# I2C0_CFG register map
Vendor: Texas Instruments
Peripheral module from a debugger description file (folder am65x).
Registers are 32-bit, access per field, reset 0x0 unless marked. A register's access mark holds for its fields unless they carry their own. Offsets are as the file gives them; lines under a group give offsets from that group; [hi:lo] are bit positions; {n}, {i} and the like mark numbered series; 'fields as' and 'values as' point back to an identical list; <NAME> marks a mode.

## I2C0_CFG
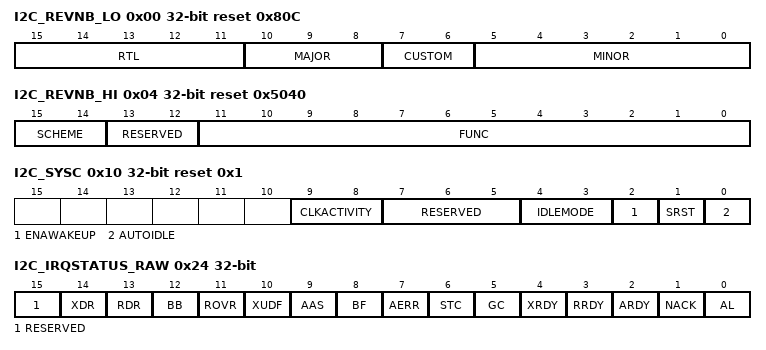
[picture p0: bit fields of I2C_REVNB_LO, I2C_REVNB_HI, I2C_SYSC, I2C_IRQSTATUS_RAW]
0x00 I2C_REVNB_LO ro reset 0x80C — Module Revision Identifier Used by software to track features, bugs, and compatibility
  [15:11] RTL — RTL version This field changes on bug fix, and resets to
  [10:8] MAJOR — Major Revision This field changes when there is a major feature change This field does not change due to bug fix, or minor feature change
  [7:6] CUSTOM — Indicates a special version for a particular device Consequence of use may avoid use of standard Chip Support Library [CSL] / Drivers 0 if non-custom
  [5:0] MINOR — Minor Revision This field changes when features are scaled up or down This field does not change due to bug fix, or major feature change
0x04 I2C_REVNB_HI ro reset 0x5040 — Module Revision Identifeir Used by software to track features, bugs, and compatibility
  [15:14] SCHEME — Used to distinguish between old Scheme and current Spare bit to encode future schemes
  [13:12] RESERVED — Reads return 0x1
  [11:0] FUNC — Function: Indicates a software compatible module family
0x10 I2C_SYSC reset 0x1 — System Configuration register
  [9:8] CLKACTIVITY rw — Clock Activity selection bits
  [7:5] RESERVED ro — Reads return 0
  [4:3] IDLEMODE rw — Idle Mode selection bits
  [2] ENAWAKEUP rw — Enable Wakeup control bit
  [1] SRST rw — SoftReset bit
  [0] AUTOIDLE rw — Autoidle bit
0x20 I2C_EOI — End Of Interrupt number specification Added Information About I2C_EOI Register The EOI register is used to re-trigger the pulse interrupt signal to ensure that any nested interrupt events are serviced. The software interrupt handler must write to the EOI register at the end of the current interrupt processing routine, so that new events can re-trigger the pulse interrupt signal again. For level interrupt signals the EOI register is not functional and must not be used.
  [0] LINE_NUMBER wo — Software End Of Interrupt (EOI) control. Write number of interrupt output.
0x24 I2C_IRQSTATUS_RAW — Per-event raw interrupt status vector. The raw status is set even if event is not enabled. Write 1 to set the (raw) status. Used mostly for debug
  [15] RESERVED rw — Write 0s for future compatibility Read returns 0
  [14] XDR rw — Transmit draining IRQ status.
  [13] RDR rw — Receive draining IRQ status.
  [12] BB ro — Bus busy status. Writing into this bit has no effect.
  [11] ROVR rw — Receive overrun status. Writing into this bit has no effect.
  [10] XUDF rw — Transmit underflow status. Writing into this bit has no effect.
  [9] AAS rw — Address recognized as slave IRQ status.
  [8] BF rw — Bus Free IRQ status.
  [7] AERR rw — Access Error IRQ status.
  [6] STC rw — Start Condition IRQ status.
  [5] GC rw — General call IRQ status. Set to 1 by core when General call address detected and interrupt signaled to IRQ_Crossbar.
  [4] XRDY rw — Transmit data ready IRQ status. Set to 1 by core when transmitter and when new data is requested. When set to 1 by core, an interrupt is signaled to IRQ_Crossbar.
  [3] RRDY rw — Receive data ready IRQ status. Set to 1 by core when receiver mode, a new data is able to be read. When set to 1 by core, an interrupt is signaled to IRQ_Crossbar.
  [2] ARDY rw — Register access ready IRQ status. When set to 1 it indicates that previous access has been performed and registers are ready to be accessed again. An interrupt is signaled to IRQ_Crossbar.
  [1] NACK rw — No acknowledgement IRQ status. Bit is set when No Acknowledge has been received, an interrupt is signaled to IRQ_Crossbar.
  [0] AL rw — Arbitration lost IRQ status. This bit is automatically set by the hardware when it loses the Arbitration in master transmit mode, an interrupt is signaled to IRQ_Crossbar. During reads, it always returns 0.
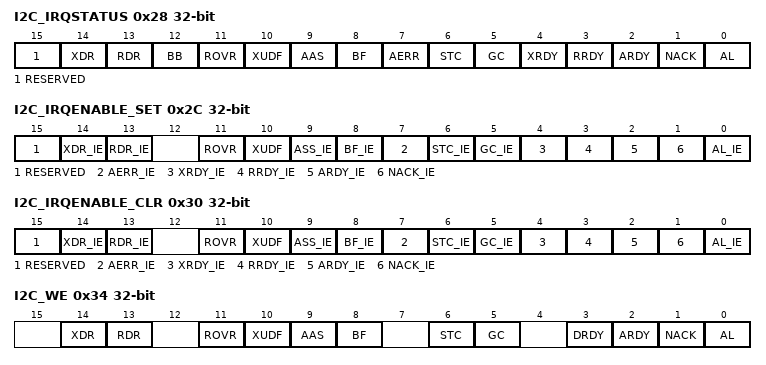
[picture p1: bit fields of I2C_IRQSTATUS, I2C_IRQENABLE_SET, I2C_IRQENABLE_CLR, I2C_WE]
0x28 I2C_IRQSTATUS — Per-event enabled interrupt status vector
  [15] RESERVED rw — Write 0s for future compatibility Read returns 0
  [14] XDR rw — Transmit draining IRQ enabled status.
  [13] RDR rw — Receive draining IRQ enabled status.
  [12] BB ro — Bus busy enabled status. Writing into this bit has no effect.
  [11] ROVR rw — Receive overrun enabled status. Writing into this bit has no effect.
  [10] XUDF rw — Transmit underflow enabled status. Writing into this bit has no effect.
  [9] AAS rw — Address recognized as slave IRQ enabled status.
  [8] BF rw — Bus Free IRQ enabled status.
  [7] AERR rw — Access Error IRQ enabled status.
  [6] STC rw — Start Condition IRQ enabled status.
  [5] GC rw — General call IRQ enabled status. Set to 1 by core when General call address detected and interrupt signaled to IRQ_Crossbar. Write 1 to clear.
  [4] XRDY rw — Transmit data ready IRQ enabled status. Set to 1 by core when transmitter and when new data is requested. When set to 1 by core, an interrupt is signaled to IRQ_Crossbar. Write 1 to clear.
  [3] RRDY rw — Receive data ready IRQ enabled status. Set to 1 by core when receiver mode, a new data is able to be read. When set to 1 by core, an interrupt is signaled to IRQ_Crossbar. Write 1 to clear.
  [2] ARDY rw — Register access ready IRQ enabled status. When set to 1 it indicates that previous access has been performed and registers are ready to be accessed again. An interrupt is signaled to IRQ_Crossbar. Write 1 to clear.
  [1] NACK rw — No acknowledgement IRQ enabled status. Bit is set when No Acknowledge has been received, an interrupt is signaled to IRQ_Crossbar. Write 1 to clear this bit.
  [0] AL rw — Arbitration lost IRQ enabled status. This bit is automatically set by the hardware when it loses the Arbitration in master transmit mode, an interrupt is signaled to IRQ_Crossbar. During reads, it always returns 0.
0x2C I2C_IRQENABLE_SET — Per-event interrupt enable bit vector.
  [15] RESERVED rw — Write 0s for future compatibility Read returns 0
  [14] XDR_IE rw — Transmit Draining interrupt enable set. Unmask the interrupt signaled by bit in
  [13] RDR_IE rw — Receive Draining interrupt enable set. Unmask the interrupt signaled by bit in
  [11] ROVR rw — Receive overrun enable set.
  [10] XUDF rw — Transmit underflow enable set.
  [9] ASS_IE rw — Addressed as Slave interrupt enable set Mask or unmask the interrupt signaled by bit in
  [8] BF_IE rw — Bus Free interrupt enable set. Unmask the interrupt signaled by bit in
  [7] AERR_IE rw — Access Error interrupt enable set. Unmask the interrupt signaled by bit in
  [6] STC_IE rw — Start Condition interrupt enable set. Unmask the interrupt signaled by bit in
  [5] GC_IE rw — General call Interrupt enable set. Unmask the interrupt signaled by bit in
  [4] XRDY_IE rw — Transmit data ready interrupt enable set. Unmask the interrupt signaled by bit in
  [3] RRDY_IE rw — Receive data ready interrupt enable set. Unmask the interrupt signaled by bit in I2C_IRQSTTUS_RAW [RRDY]
  [2] ARDY_IE rw — Register access ready interrupt enable set. Unmask the interrupt signaled by bit in
  [1] NACK_IE rw — No acknowledgement interrupt enable set. Unmask the interrupt signaled by bit in
  [0] AL_IE rw — Arbitration lost interrupt enable set. Unmask the interrupt signaled by bit in
0x30 I2C_IRQENABLE_CLR — Per-event interrupt clear bit vector.
  [15] RESERVED rw — Write 0s for future compatibility Read returns 0
  [14] XDR_IE rw — Transmit Draining interrupt enable clear. Mask the interrupt signaled by bit in
  [13] RDR_IE rw — Receive Draining interrupt enable clear. Mask the interrupt signaled by bit in I2C_IRQSTAUS_RAW [RDR].
  [11] ROVR rw — Receive overrun enable clear.
  [10] XUDF rw — Transmit underflow enable clear.
  [9] ASS_IE rw — Addressed as Slave interrupt enable clear Mask or unmask the interrupt signaled by bit in
  [8] BF_IE rw — Bus Free interrupt enable clear. Mask the interrupt signaled by bit in
  [7] AERR_IE rw — Access Error interrupt enable clear. Mask the interrupt signaled by bit in
  [6] STC_IE rw — Start Condition interrupt enable clear. Mask the interrupt signaled by bit in
  [5] GC_IE rw — General call Interrupt enable clear. Mask the interrupt signaled by bit in
  [4] XRDY_IE rw — Transmit data ready interrupt enable clear. Mask the interrupt signaled by bit in
  [3] RRDY_IE rw — Receive data ready interrupt enable clear. Mask the interrupt signaled by bit in I2C_IRQSTAUS_RAW [RRDY]
  [2] ARDY_IE rw — Register access ready interrupt enable clear. Mask the interrupt signaled by bit in
  [1] NACK_IE rw — No acknowledgement interrupt enable clear. Mask the interrupt signaled by bit in
  [0] AL_IE rw — Arbitration lost interrupt enable clear. Mask the interrupt signaled by bit in
0x34 I2C_WE — I2C wakeup enable vector.
  [14] XDR rw — Transmit Draining wakeup set.
  [13] RDR rw — Receive Draining wakeup set.
  [11] ROVR rw — Receive overrun wakeup set.
  [10] XUDF rw — Transmit underflow wakeup set.
  [9] AAS rw — Address as slave IRQ wakeup set.
  [8] BF rw — Bus Free IRQ wakeup set.
  [6] STC rw — Start Condition IRQ wakeup set.
  [5] GC rw — General call IRQ wakeup set.
  [3] DRDY rw — Receive/Transmit data ready IRQ wakeup set.
  [2] ARDY rw — Register access ready IRQ wakeup set.
  [1] NACK rw — No acknowledgment IRQ wakeup set.
  [0] AL rw — Arbitration lost IRQ wakeup set.
0x38 I2C_DMARXENABLE_SET — Per-event DMA RX enable set.
  [0] DMARX_ENABLE_SET rw — Receive DMA channel enable set.
0x3C I2C_DMATXENABLE_SET — Per-event DMA TX enable set.
  [0] DMATX_ENABLE_SET rw — Transmit DMA channel enable set.
0x40 I2C_DMARXENABLE_CLR — Per-event DMA RX enable clear.
  [0] DMARX_ENABLE_CLEAR rw — Receive DMA channel enable clear.
0x44 I2C_DMATXENABLE_CLR — Per-event DMA TX enable clear.
  [0] DMATX_ENABLE_CLEAR rw — Transmit DMA channel enable clear.
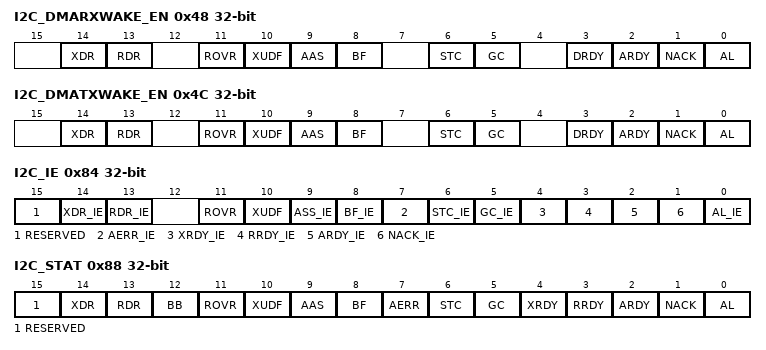
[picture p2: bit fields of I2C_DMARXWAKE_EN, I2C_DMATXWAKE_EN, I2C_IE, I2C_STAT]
0x48 I2C_DMARXWAKE_EN — Per-event DMA RX wakeup enable.
  fields as I2C_WE
0x4C I2C_DMATXWAKE_EN — Per-event DMA TX wakeup enable.
  fields as I2C_WE
0x84 I2C_IE — I2C interrupt enable vector (legacy).
  [15] RESERVED rw — Write 0s for future compatibility Read returns 0
  [14] XDR_IE rw — Transmit Draining interrupt enable Mask or unmask the interrupt signaled by bit in
  [13] RDR_IE rw — Receive Draining interrupt enable Mask or unmask the interrupt signaled by bit in
  [11] ROVR rw — Receive overrun enable set
  [10] XUDF rw — Transmit underflow enable set
  [9] ASS_IE rw — Addressed as Slave interrupt enable Mask or unmask the interrupt signaled by bit in
  [8] BF_IE rw — Bus Free interrupt enable Mask or unmask the interrupt signaled by bit in
  [7] AERR_IE rw — Access Error interrupt enable Mask or unmask the interrupt signaled by bit in
  [6] STC_IE rw — Start Condition interrupt enable Mask or unmask the interrupt signaled by bit in
  [5] GC_IE rw — General call Interrupt enable Mask or unmask the interrupt signaled by bit in
  [4] XRDY_IE rw — Transmit data ready interrupt enable Mask or unmask the interrupt signaled by bit in
  [3] RRDY_IE rw — Receive data ready interrupt enable Mask or unmask the interrupt signaled by bit in
  [2] ARDY_IE rw — Register access ready interrupt enable Mask or unmask the interrupt signaled by bit in
  [1] NACK_IE rw — No acknowledgement interrupt enable Mask or unmask the interrupt signaled by bit in
  [0] AL_IE rw — Arbitration lost interrupt enable Mask or unmask the interrupt signaled by bit in
0x88 I2C_STAT — I2C interrupt status vector (legacy).
  [15] RESERVED rw — Write 0s for future compatibility Read returns 0
  [14] XDR rw — Transmit draining IRQ status
  [13] RDR rw — Receive draining IRQ status
  [12] BB ro — Bus busy statusWriting into this bit has no effect
  [11] ROVR rw — Receive overrun statusWriting into this bit has no effect
  [10] XUDF rw — Transmit underflow statusWriting into this bit has no effect
  [9] AAS rw — Address recognized as slave IRQ status
  [8] BF rw — Bus Free IRQ status
  [7] AERR rw — Access Error IRQ status
  [6] STC rw — Start Condition IRQ status
  [5] GC rw — General call IRQ status Set to '1' by core when General call address detected and interrupt signaled to MPUSS Write '1' to clear
  [4] XRDY rw — Transmit data ready IRQ status Set to '1' by core when transmitter and when new data is requested When set to '1' by core, an interrupt is signaled to MPUSS Write '1' to clear
  [3] RRDY rw — Receive data ready IRQ status Set to '1' by core when receiver mode, a new data is able to be read When set to '1' by core, an interrupt is signaled to MPUSS Write '1' to clear
  [2] ARDY rw — Register access ready IRQ status When set to '1' it indicates that previous access has been performed and registers are ready to be accessed again An interrupt is signaled to MPUSS Write '1' to clear
  [1] NACK rw — No acknowledgement IRQ status Bit is set when No Acknowledge has been received, an interrupt is signaled to MPUSS Write '1' to clear this bit
  [0] AL rw — Arbitration lost IRQ status This bit is automatically set by the hardware when it loses the Arbitration in master transmit mode, an interrupt is signaled to MPUSS During reads, it always returns 0
0x90 I2C_SYSS ro — System Status register
  [0] RDONE — Reset done bit
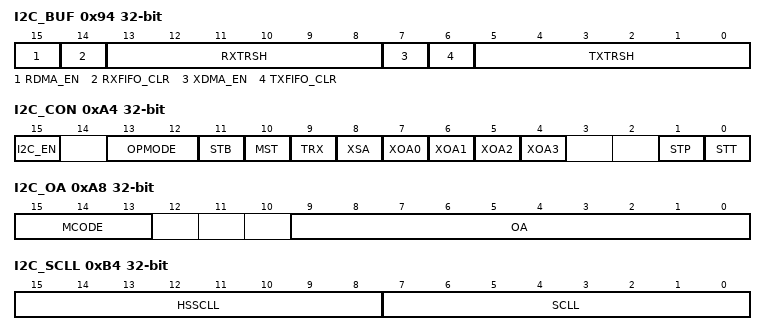
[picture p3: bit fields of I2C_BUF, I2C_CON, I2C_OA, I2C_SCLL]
0x94 I2C_BUF rw — Buffer Configuration register
  [15] RDMA_EN — Receive DMA channel enable
  [14] RXFIFO_CLR — Receive FIFO clear
  [13:8] RXTRSH — Threshold value for FIFO buffer in RX mode
  [7] XDMA_EN — Transmit DMA channel enable
  [6] TXFIFO_CLR — Transmit FIFO clear
  [5:0] TXTRSH — Threshold value for FIFO buffer in TX mode
0x98 I2C_CNT rw — Data counter register
  [15:0] DCOUNT — Data count
0x9C I2C_DATA — Data access register
  [7:0] DATA rw — Transmit/Receive data FIFO endpoint
0xA4 I2C_CON — I2C configuration register.
  [15] I2C_EN rw — I2C module enable.
  [13:12] OPMODE rw — Operation mode selection.
  [11] STB rw — Start byte mode (master mode only).
  [10] MST rw — Master/slave mode.
  [9] TRX rw — Transmitter/Receiver mode (master mode only).
  [8] XSA rw — Expand Slave address.
  [7-n] XOA{n} rw (n=0..3) — Expand Own address {n}.
  [1] STP rw — Stop condition (master mode only).
  [0] STT rw — Start condition (master mode only).
0xA8 I2C_OA — Own address register
  [15:13] MCODE rw — Master Code
  [9:0] OA rw — Own address
0xAC I2C_SA reset 0x3FF — Slave address register
  [9:0] SA rw — Slave address
0xB0 I2C_PSC — I2C Clock Prescaler Register
  [7:0] PSC rw — Fast/Standard mode prescale sampling clock divider value
0xB4 I2C_SCLL rw — I2C SCL Low Time Register.
  [15:8] HSSCLL — High speed mode SCL low time
  [7:0] SCLL — Fast/standard mode SCL low time
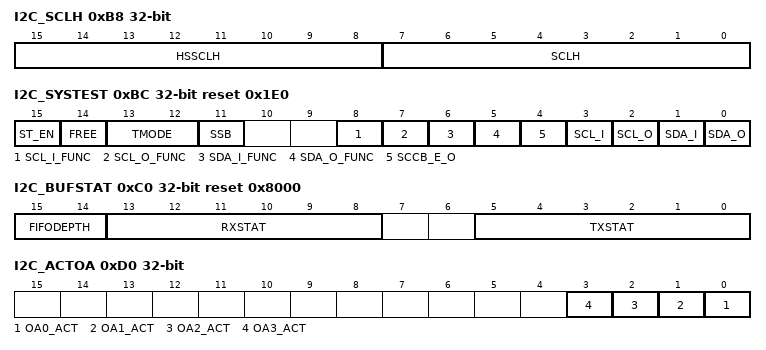
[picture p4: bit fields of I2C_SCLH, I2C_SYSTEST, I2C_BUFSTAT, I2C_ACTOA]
0xB8 I2C_SCLH rw — I2C SCL High Time Register.
  [15:8] HSSCLH — High speed mode SCL high time
  [7:0] SCLH — Fast/standard mode SCL high time
0xBC I2C_SYSTEST reset 0x1E0 — I2C System Test Register.
  [15] ST_EN rw — System test enable.
  [14] FREE rw — Free running mode (on breakpoint)
  [13:12] TMODE rw — Test mode select.
  [11] SSB rw — Set all status bits in
  [8] SCL_I_FUNC ro — SCL line input value (functional mode).
  [7] SCL_O_FUNC ro — SCL line output value (functional mode).
  [6] SDA_I_FUNC ro — SDA line input value (functional mode).
  [5] SDA_O_FUNC ro — SDA line output value (functional mode).
  [4] SCCB_E_O rw — SCCB_E line sense output value
  [3] SCL_I ro — SCL line sense input value
  [2] SCL_O rw — SCL line drive output value.
  [1] SDA_I ro — SDA line sense input value.
  [0] SDA_O rw — SDA line drive output value.
0xC0 I2C_BUFSTAT ro reset 0x8000 — I2C Buffer Status Register.
  [15:14] FIFODEPTH — Internal FIFO buffers depth.
  [13:8] RXSTAT — RX Buffer Status
  [5:0] TXSTAT — TX Buffer Status.
{0xC0+4i} I2C_OA{i} (i=1..3) — I2C Own Address {i} Register
  [9:0] OA{i} rw — Own address {i}
0xD0 I2C_ACTOA ro — I2C Active Own Address Register.
  [n] OA{n}_ACT (n=0..3) — Own Address {n} active.
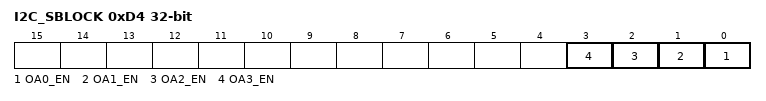
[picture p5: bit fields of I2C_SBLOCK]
0xD4 I2C_SBLOCK — I2C Clock Blocking Enable Register.
  [n] OA{n}_EN rw (n=0..3) — Enable I2C Clock Blocking for Own Address {n}.
